# DEBUGSS_WRAP_JTAGAP_CFG_0_000700002500h register map
Vendor: Texas Instruments
Peripheral module from a debugger description file (folder AM275x).
Registers are 32-bit, read-write, reset 0x0 unless marked. A register's access mark holds for its fields unless they carry their own. Offsets are as the file gives them; lines under a group give offsets from that group; [hi:lo] are bit positions; {n}, {i} and the like mark numbered series; 'fields as' and 'values as' point back to an identical list; <NAME> marks a mode.

## jtagap_cfg_0
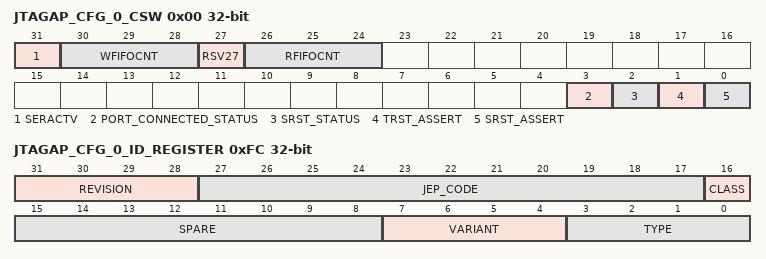
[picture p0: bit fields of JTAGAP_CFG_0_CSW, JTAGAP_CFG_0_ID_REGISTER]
0x00 JTAGAP_CFG_0_CSW access per field — This register provides control and status information
  [31] SERACTV ro — JTAG Serializer active
  [30:28] WFIFOCNT ro — Outstanding Write FIFO Byte Count
  [27] RSV27 ro — Reserved, returns 0
  [26:24] RFIFOCNT ro — Outstanding Read FIFO Byte Count
  [3] PORT_CONNECTED_STATUS ro — Reading this returns the Port connected status of the selected port
  [2] SRST_STATUS ro — Reading this returns the SRST status of the selected port If multiple ports are selected, it is the AND of all the SRSTCONNECTED inputs from the selected ports
  [1] TRST_ASSERT rw — Writing a 1 causes TRST to be asserted
  [0] SRST_ASSERT rw — Writing a 1 causes SRST to be asserted
0x04 JTAGAP_CFG_0_PSEL_REG — This 8-bit register is used to select the JTAG port.
  [7:0] PORT_SELECT_REGISTER
0x08 JTAGAP_CFG_0_PSTA_REG — A bit value of 1 indicates that a selected and enabled port has gone inactive. These bits are sticky. Writing a 1 to them clears them.
  [31:0] PORT_STATUS_REGISTER
0x10 JTAGAP_CFG_0_BYTEFIFO1 — Reading this location reads a byte from the FIFO. Writing it loads a byte into the FIFO. Reset value is UNDEFINED
  [7:0] BYTE_FIFO_1
{0xC+4i} JTAGAP_CFG_0_BYTEFIFO{i} (i=2..4) — Reading this location reads a {8i} bits from the FIFO. Writing it loads {8i} bits into the FIFO. Reset value is UNDEFINED
  [{8i-1}:0] BYTE_FIFO_{i}
0xFC JTAGAP_CFG_0_ID_REGISTER ro — Reading this register returns the ID information for this AP.
  [31:28] REVISION — Device Revision [1]
  [27:17] JEP_CODE — Device JEP Code [0x23B]
  [16] CLASS — Device Class[0] [not a memory access port]
  [15:8] SPARE — Spare, returns 0
  [7:4] VARIANT — Device Variant [1]
  [3:0] TYPE — Device Type: 0=JTAG, 1=AHB, 2=APB [0]
